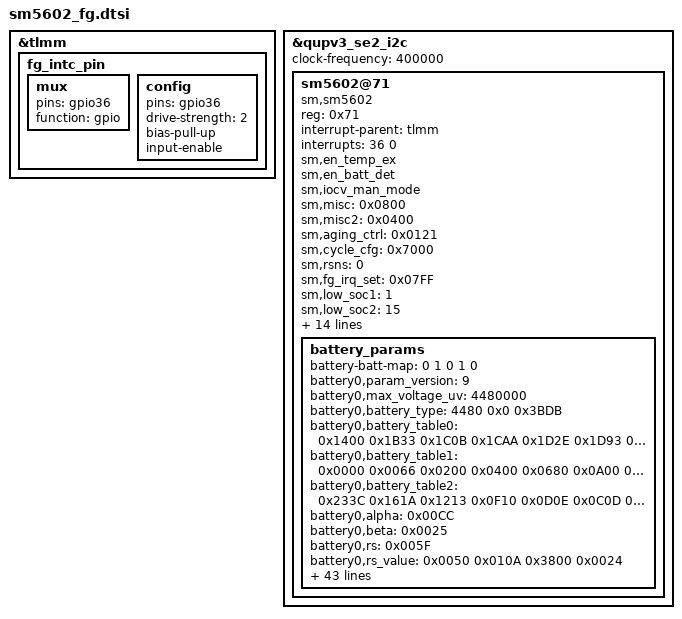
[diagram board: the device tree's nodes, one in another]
/* GPIO_36 : FG_INT_N */

&tlmm {
        fg_intc_pin: fg_intc_pin {
                mux {
                        pins = "gpio36";
                        function = "gpio";
                };
                config {
                        pins = "gpio36";
                        drive-strength = <2>; /* 2 mA */
                        bias-pull-up;         /* PULL DOWN */
                        input-enable;
                };
        };
};

&qupv3_se2_i2c {
	status = "okay";
	clock-frequency = <400000>;

	sm5602@71 {
		compatible = "sm,sm5602";
		reg = <0x71>;
		interrupt-parent = <&tlmm>;
		interrupts = <36 0>;
		//mtk,irq-gpio = <&pio 36 0x0>;
		sm,en_temp_ex;
		//sm,en_temp_in;
		//sm,en_temp_3rd;
		sm,en_batt_det;
		sm,iocv_man_mode;
		sm,misc = <0x0800>;
		sm,misc2 = <0x0400>;
		sm,aging_ctrl = <0x0121>;
		sm,cycle_cfg = <0x7000>;
		sm,rsns = <0>;
		sm,fg_irq_set = <0x07FF>;
		sm,low_soc1 = <1>;
		sm,low_soc2 = <15>;
		sm,v_l_alarm = <3400>;
		sm,v_h_alarm = <4480>;
		sm,battery_table_num = <0>;
		sm,param_version = <0>;
		sm,t_l_alarm_in = <49>;
		sm,t_h_alarm_in = <1>;
		sm,t_l_alarm_ex = <0xE8E0>;
		sm,t_h_alarm_ex = <0x9E2B>;
		sm,shutdown-delay-enable;
		sm,rtrace = <0>;
		sm,rpara = <0x0>;
		sm,curr_voffset = <0>;
		sm,curr_vslope = <0x8080>;
		io-channels =
			<&pm6125_vadc ADC5_GPIO4_100K_PU>;
		io-channel-names =
			"batt_id";
		battery_params {
			battery-batt-map = <0 1 0 1 0>;
			//ATL battery
			battery0,param_version = <9>;
			battery0,max_voltage_uv = <4480000>;
			battery0,battery_type = <4480 0x0 0x3BDB>;
			battery0,battery_table0 = <0x1400 0x1B33 0x1C0B 0x1CAA 0x1D2E 0x1D93 0x1DDB 0x1E15 0x1E3C 0x1E4D 0x1E62 0x1E82 0x1EAF 0x1EEE 0x1F91 0x2013 0x2079 0x20E8 0x2192 0x2220 0x226C 0x22DE 0x235F 0x2666>;
			battery0,battery_table1 = <0x0000 0x0066 0x0200 0x0400 0x0680 0x0A00 0x0E80 0x1519 0x1A19 0x1F19 0x2419 0x2933 0x2E33 0x3333 0x3ACC 0x424C 0x474C 0x4C66 0x53E6 0x59E6 0x5D00 0x6100 0x6400 0x64E6>;
			battery0,battery_table2 = <0x233C 0x161A 0x1213 0x0F10 0x0D0E 0x0C0D 0x0B0C 0x0B0B>;
			battery0,alpha = <0x00CC>;
			battery0,beta = <0x0025>;
			battery0,rs = <0x005F>;
			battery0,rs_value = <0x0050 0x010A 0x3800 0x0024>;
			battery0,vit_period = <0x315A>;
			battery0,volt_cal = <0x8000>;
			battery0,mix_value = <0x0003>;
			battery0,curr_offset = <0x000>;
			battery0,curr_slope = <0x8088>;
			battery0,topoff_soc = <7 500 500>;
			battery0,temp_std = <25>;
			battery0,temp_offset = <0 11 1 0 8 (-1)>;
			battery0,temp_cal = <0 6 1 11 (-1) 0 6 1 9 1>;
			battery0,ext_temp_cal = <0 2 1 2 1 1 2 7 2 9>;
			battery0,tem_poff = <3410 40>;
			battery0,static_scale_soc = <1 991 1000 (-50) 50 1>;
			battery0,thermal_table = <
				0x506E 0x4F35 0x4E07 0x4CC0 0x4B76 0x4A25 0x48BD 0x475D 0x45F5 0x4477
				0x4304 0x4175 0x3FDE 0x3E4A 0x3CA2 0x3AF6 0x3945 0x378A 0x35CB 0x33FC
				0x322B 0x3059 0x2E82 0x2CA0 0x2AC6 0x28C6 0x26E0 0x24EA 0x22E8 0x20EF
				0x1EE7 0x1CEE 0x1AE8 0x18D0 0x16D6 0x14CE 0x12F3 0x10E4 0x0ED6 0x0CC4
				0x0ABC 0x08BC 0x06A8 0x04AD 0x02A1 0x009E 0xF669 0xF471 0xF278 0xF081
				0xEE7B 0xEC8C 0xEAA1 0xE8BE 0xE6E1 0xE505 0xE332 0xE162 0xDF9B 0xDDD9
				0xDC1F 0xDA67 0xD8B4 0xD70B 0xD565 0xD3C7 0xD232 0xD0A1 0xCF18 0xCD94
				0xCC18 0xCAA5 0xC936 0xC7D3 0xC670 0xC519 0xC3C6 0xC27A 0xC136 0xBFF7
				0xBEC1 0xBD92 0xBC6E 0xBB4D 0xBA36 0xB922 0xB816 0xB712 0xB611 0xB517
				0xB422 0xB334 0xB249 0xB164 0xB085 0xAFAD 0xAED8 0xAE0A 0xAD3E 0xAC78
				0xABB7>;			//NTC value(DEC) table -20~80 20K PU,20K PD/10K NTC

			//LWN battery
			battery1,param_version = <9>;
			battery1,max_voltage_uv = <4480000>;
			battery1,battery_type = <4480 0x0 0x3B3F>;
			battery1,battery_table0 = <0x1400 0x1B33 0x1C15 0x1C95 0x1D16 0x1D95 0x1DE5 0x1E0F 0x1E47 0x1E5B 0x1E77 0x1E9E 0x1EF3 0x1F67 0x1FC9 0x2059 0x20C8 0x213A 0x21B0 0x222F 0x229C 0x2307 0x2369 0x2666>;
			battery1,battery_table1 = <0x0000 0x0066 0x0200 0x0400 0x0680 0x0A19 0x0F33 0x144C 0x1BE6 0x2100 0x2600 0x2B19 0x32B3 0x37CC 0x3CE6 0x4480 0x4999 0x4EB3 0x53B3 0x58CC 0x5CE6 0x6100 0x6400 0x64E6>;
			battery1,battery_table2 = <0x2037 0x1418 0x1112 0x0D0F 0x0C0D 0x0B0B 0x0A0B 0x0A0A>;
			battery1,alpha = <0x00CC>;
			battery1,beta = <0x0025>;
			battery1,rs = <0x005F>;
			battery1,rs_value = <0x0050 0x010A 0x3800 0x0024>;
			battery1,vit_period = <0x315A>; 
			battery1,volt_cal = <0x8000>; 
			battery1,mix_value = <0x0003>; 
			battery1,curr_offset = <0x0000>; 
			battery1,curr_slope = <0x8080>;
			battery1,topoff_soc = <7 500 500>;
			battery1,temp_std = <25>;
			battery1,temp_offset = <0 11 1 0 8 (-1)>;
			battery1,temp_cal = <0 6 1 11 (-1) 0 6 1 9 1>;
			battery1,ext_temp_cal = <0 2 1 2 1 1 2 7 2 9>;
			battery1,tem_poff = <3410 40>;
			battery1,static_scale_soc = <1 991 1000 (-50) 50 1>;
			battery1,thermal_table = <
				0x506E 0x4F35 0x4E07 0x4CC0 0x4B76 0x4A25 0x48BD 0x475D 0x45F5 0x4477
				0x4304 0x4175 0x3FDE 0x3E4A 0x3CA2 0x3AF6 0x3945 0x378A 0x35CB 0x33FC
				0x322B 0x3059 0x2E82 0x2CA0 0x2AC6 0x28C6 0x26E0 0x24EA 0x22E8 0x20EF
				0x1EE7 0x1CEE 0x1AE8 0x18D0 0x16D6 0x14CE 0x12F3 0x10E4 0x0ED6 0x0CC4
				0x0ABC 0x08BC 0x06A8 0x04AD 0x02A1 0x009E 0xF669 0xF471 0xF278 0xF081
				0xEE7B 0xEC8C 0xEAA1 0xE8BE 0xE6E1 0xE505 0xE332 0xE162 0xDF9B 0xDDD9
				0xDC1F 0xDA67 0xD8B4 0xD70B 0xD565 0xD3C7 0xD232 0xD0A1 0xCF18 0xCD94
				0xCC18 0xCAA5 0xC936 0xC7D3 0xC670 0xC519 0xC3C6 0xC27A 0xC136 0xBFF7
				0xBEC1 0xBD92 0xBC6E 0xBB4D 0xBA36 0xB922 0xB816 0xB712 0xB611 0xB517
				0xB422 0xB334 0xB249 0xB164 0xB085 0xAFAD 0xAED8 0xAE0A 0xAD3E 0xAC78
				0xABB7>;  //NTC value(DEC) table -20~80 20K PU,20K PD/10K NTC
		};
	};
};
